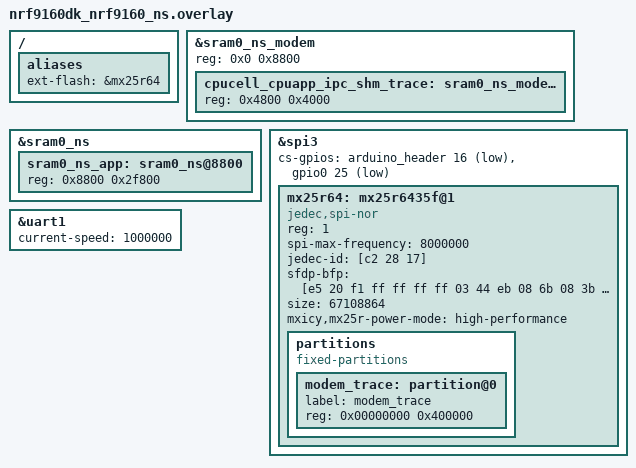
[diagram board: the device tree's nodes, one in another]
/*
 * Copyright (c) 2022 Nordic Semiconductor ASA
 *
 * SPDX-License-Identifier: LicenseRef-Nordic-5-Clause
 */

#include <samples/cellular/nrf91_no_bootloader_partitions.dtsi>

#include <samples/cellular/nrf91_sram_partitions.dtsi>

/* Increase modem (shared) memory. */
&sram0_ns_modem {
	reg = <0x0 0x8800>;
	ranges = <0x0 0x0 0x8800>;

	cpucell_cpuapp_ipc_shm_trace: sram0_ns_modem@4800 {
		/* Modem trace memory */
		reg = <0x4800 0x4000>;
	};
};

/* Delete Non-Secure application memory so we can move and shrink it. */
/delete-node/ &sram0_ns_app;

&sram0_ns {
	sram0_ns_app: sram0_ns@8800 {
		/* Redefine smaller Non-Secure application memory. */
		reg = <0x8800 0x2f800>;
	};
};

/* The mx25r64 definition would normally be included when specifying a nrf9160dk_nrf9160_ns
 * board revision >= 0.14.0, but unfortunately twister has a bug that prevents the revision
 * overlay to get loaded when testing the sample.
 */
&spi3 {
	cs-gpios = <&arduino_header 16 GPIO_ACTIVE_LOW>, /* D10 */
		   <&gpio0 25 GPIO_ACTIVE_LOW>;

	mx25r64: mx25r6435f@1 {
		compatible = "jedec,spi-nor";
		reg = <1>;
		status = "okay";
		spi-max-frequency = <8000000>;
		jedec-id = [c2 28 17];
		sfdp-bfp = [e5 20 f1 ff ff ff ff 03 44 eb 08 6b 08 3b 04 bb
			    ee ff ff ff ff ff 00 ff ff ff 00 ff 0c 20 0f 52
			    10 d8 00 ff 23 72 f5 00 82 ed 04 cc 44 83 68 44
			    30 b0 30 b0 f7 c4 d5 5c 00 be 29 ff f0 d0 ff ff];
		size = <67108864>;
		mxicy,mx25r-power-mode = "high-performance";

		partitions {
			compatible = "fixed-partitions";
			#address-cells = <1>;
			#size-cells = <1>;

			modem_trace: partition@0 {
				label = "modem_trace";
				reg = <0x00000000 0x400000>;
			};
		};
	};
};

/* Enable UART1 at 1 megabaud for printing modem traces  */
&uart1 {
	status = "okay";
	current-speed = <1000000>;
};

/ {
	aliases {
		ext-flash = &mx25r64;
	};
};
